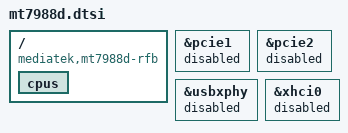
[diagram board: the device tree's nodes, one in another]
// SPDX-License-Identifier: (GPL-2.0 OR MIT)
/*
 * Copyright (C) 2021 MediaTek Inc.
 * Author: Sam.Shih <sam.shih@mediatek.com>
 */

#include "mt7988a.dtsi"

/ {
	compatible = "mediatek,mt7988d-rfb";

	cpus {
		/delete-node/ cpu@3;
	};
};

&pcie1 {
	status = "disabled";
};

&pcie2 {
	status = "disabled";
};

&usbxphy {
	status = "disabled";
};

&xhci0 {
	status = "disabled";
};
